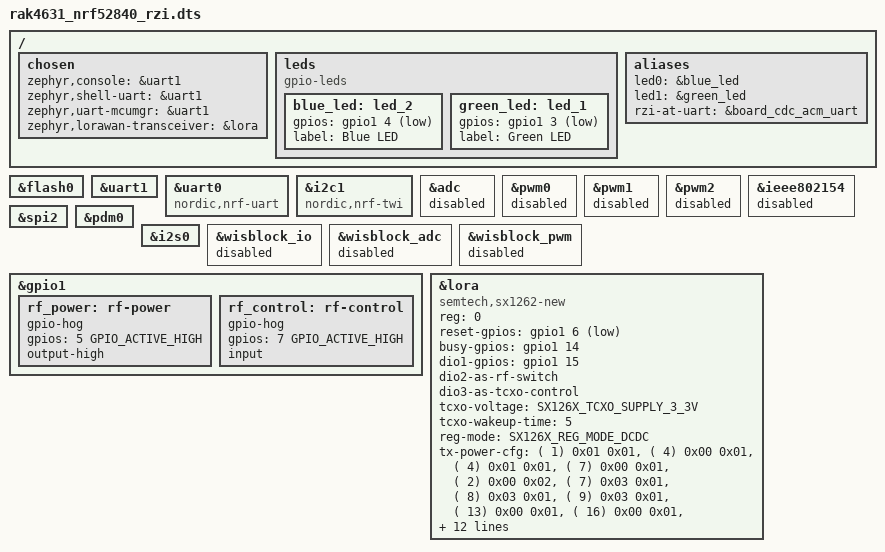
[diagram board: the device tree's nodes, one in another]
/* SPDX-FileCopyrightText: Copyright (c) 2026 RAKwireless */
/* SPDX-License-Identifier: Apache-2.0 */

#include <../boards/rakwireless/rak4631/rak4631.dts>
#include <zephyr/dt-bindings/usp/sx126x.h>

/* Both MCUboot and the application use this variant's RZI flash layout. */
&flash0 {
	/delete-node/ partitions;
};

#include "rak4631-rzi-partitions.dtsi"

/ {
	chosen {
		/delete-property/ zephyr,ieee802154;
		/delete-property/ zephyr,bt-mon-uart;
		/delete-property/ zephyr,bt-c2h-uart;
		zephyr,console = &uart1;
		zephyr,shell-uart = &uart1;
		zephyr,uart-mcumgr = &uart1;
		zephyr,lorawan-transceiver = &lora;
	};

	leds {
		compatible = "gpio-leds";

		blue_led: led_2 {
			gpios = <&gpio1 4 GPIO_ACTIVE_LOW>;
			label = "Blue LED";
		};

		green_led: led_1 {
			gpios = <&gpio1 3 GPIO_ACTIVE_LOW>;
			label = "Green LED";
		};
	};

	aliases {
		led0 = &blue_led;
		led1 = &green_led;
		rzi-at-uart = &board_cdc_acm_uart;
	};
};

&uart1 {
	status = "okay";
};

/* Retain the validated board's peripheral types and disabled defaults. */
&uart0 {
	compatible = "nordic,nrf-uart";
};

&i2c1 {
	compatible = "nordic,nrf-twi";
};

&adc {
	status = "disabled";
	/delete-node/ channel@2;
	/delete-node/ channel@3;
	/delete-node/ channel@4;
	/delete-node/ channel@7;
};

&pwm0 {
	status = "disabled";
	/delete-property/ pinctrl-0;
	/delete-property/ pinctrl-1;
	/delete-property/ pinctrl-names;
};

&pwm1 {
	status = "disabled";
	/delete-property/ pinctrl-0;
	/delete-property/ pinctrl-1;
	/delete-property/ pinctrl-names;
};

&pwm2 {
	status = "disabled";
	/delete-property/ pinctrl-0;
	/delete-property/ pinctrl-1;
	/delete-property/ pinctrl-names;
};

&ieee802154 {
	status = "disabled";
};

&spi2 {
	/delete-property/ cs-gpios;
	/delete-property/ pinctrl-0;
	/delete-property/ pinctrl-1;
	/delete-property/ pinctrl-names;
};

&pdm0 {
	/delete-property/ pinctrl-0;
	/delete-property/ pinctrl-names;
};

&i2s0 {
	/delete-property/ pinctrl-0;
	/delete-property/ pinctrl-names;
};

&wisblock_io {
	status = "disabled";
};

&wisblock_adc {
	status = "disabled";
};

&wisblock_pwm {
	status = "disabled";
};

&gpio1 {
	rf_power: rf-power {
		gpio-hog;
		gpios = <5 GPIO_ACTIVE_HIGH>;
		output-high;
	};

	rf_control: rf-control {
		gpio-hog;
		gpios = <7 GPIO_ACTIVE_HIGH>;
		input;
	};
};

/* Replace native Zephyr SX1262 properties with the USP binding. */
&lora {
	/delete-property/ rx-enable-gpios;
	/delete-property/ dio2-tx-enable;
	/delete-property/ dio3-tcxo-voltage;
	/delete-property/ tcxo-power-startup-delay-ms;
	compatible = "semtech,sx1262-new";
	reg = <0>;
	reset-gpios = <&gpio1 6 GPIO_ACTIVE_LOW>;
	busy-gpios = <&gpio1 14 GPIO_ACTIVE_HIGH>;
	dio1-gpios = <&gpio1 15 (GPIO_ACTIVE_HIGH | GPIO_PULL_DOWN)>;
	dio2-as-rf-switch;
	dio3-as-tcxo-control;
	tcxo-voltage = <SX126X_TCXO_SUPPLY_3_3V>;
	tcxo-wakeup-time = <5>;
	reg-mode = <SX126X_REG_MODE_DCDC>;
	/* SX1262 PA table, one entry per dBm from -9 to 22. */
	tx-power-cfg =
		<(  1) 0x01 0x01>,
		<(  4) 0x00 0x01>,
		<(  4) 0x01 0x01>,
		<(  7) 0x00 0x01>,
		<(  2) 0x00 0x02>,
		<(  7) 0x03 0x01>,
		<(  8) 0x03 0x01>,
		<(  9) 0x03 0x01>,
		<( 13) 0x00 0x01>,
		<( 16) 0x00 0x01>,
		<( 19) 0x00 0x01>,
		<( 20) 0x00 0x01>,
		<( 18) 0x03 0x01>,
		<( 21) 0x00 0x01>,
		<( 16) 0x00 0x02>,
		<( 22) 0x00 0x01>,
		<( 22) 0x01 0x01>,
		<( 22) 0x02 0x01>,
		<( 22) 0x03 0x01>,
		<( 22) 0x04 0x01>,
		<( 22) 0x00 0x02>,
		<( 22) 0x01 0x02>,
		<( 22) 0x02 0x02>,
		<( 22) 0x03 0x02>,
		<( 22) 0x01 0x03>,
		<( 22) 0x02 0x03>,
		<( 22) 0x00 0x05>,
		<( 22) 0x01 0x05>,
		<( 22) 0x02 0x05>,
		<( 22) 0x03 0x06>,
		<( 22) 0x04 0x06>,
		<( 22) 0x04 0x07>;
	spi-max-frequency = <1000000>;
};
